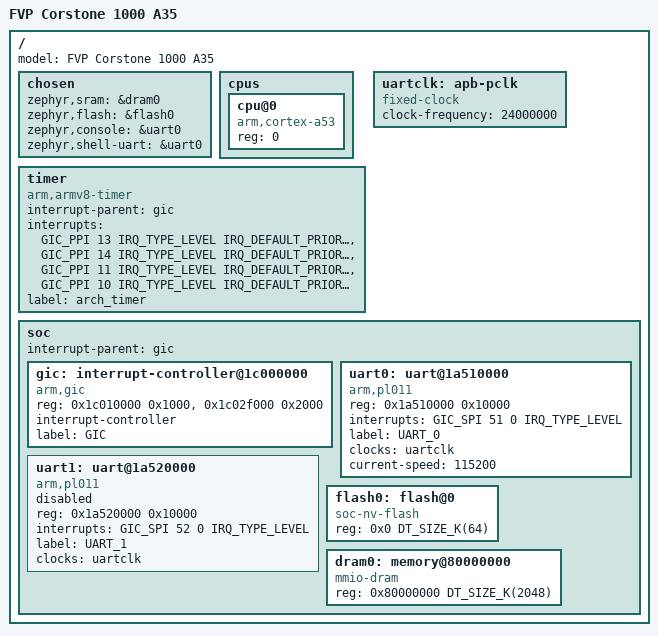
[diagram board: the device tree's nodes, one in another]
/*
 * Copyright (c) 2021 Carlo Caione <ccaione@baylibre.com>
 * SPDX-License-Identifier: Apache-2.0
 */

/dts-v1/;

#include <mem.h>
#include <arm64/armv8-a.dtsi>
#include <dt-bindings/interrupt-controller/arm-gic.h>

/ {
	model = "FVP Corstone 1000 A35";

	chosen {
		/*
		 * The SRAM node is actually located in the
		 * DRAM region of the FVP Base RevC 2xAEMv8A.
		 */
		zephyr,sram = &dram0;
		zephyr,flash = &flash0;
		zephyr,console = &uart0;
		zephyr,shell-uart = &uart0;
	};

	cpus {
		#address-cells = <1>;
		#size-cells = <0>;

		cpu@0 {
			device_type = "cpu";
			compatible = "arm,cortex-a53";
			reg = <0>;
		};
	};

	timer {
		compatible = "arm,armv8-timer";
		interrupt-parent = <&gic>;
		interrupts = <GIC_PPI 13 IRQ_TYPE_LEVEL
			      IRQ_DEFAULT_PRIORITY>,
			     <GIC_PPI 14 IRQ_TYPE_LEVEL
			      IRQ_DEFAULT_PRIORITY>,
			     <GIC_PPI 11 IRQ_TYPE_LEVEL
			      IRQ_DEFAULT_PRIORITY>,
			     <GIC_PPI 10 IRQ_TYPE_LEVEL
			      IRQ_DEFAULT_PRIORITY>;
		label = "arch_timer";
	};

	uartclk: apb-pclk {
		compatible = "fixed-clock";
		clock-frequency = <24000000>;
		#clock-cells = <0>;
	};

	soc {
		interrupt-parent = <&gic>;

		gic: interrupt-controller@1c000000 {
			compatible = "arm,gic";
			reg = <0x1c010000 0x1000>, // GIC Distributor
			      <0x1c02f000 0x2000>; // GIC CPU Interface
			interrupt-controller;
			#interrupt-cells = <4>;
			label = "GIC";
			status = "okay";
			#address-cells = <1>;
			#size-cells = <1>;
		};

		uart0: uart@1a510000 {
			compatible = "arm,pl011";
			reg = <0x1a510000 0x10000>;
			status = "disabled";
			interrupts = <GIC_SPI 51 0 IRQ_TYPE_LEVEL>;
			interrupt-names = "irq_51";
			label = "UART_0";
			clocks = <&uartclk>;
		};

		uart1: uart@1a520000 {
			compatible = "arm,pl011";
			reg = <0x1a520000 0x10000>;
			status = "disabled";
			interrupts = <GIC_SPI 52 0 IRQ_TYPE_LEVEL>;
			interrupt-names = "irq_52";
			label = "UART_1";
			clocks = <&uartclk>;
		};

		flash0: flash@0 {
			compatible = "soc-nv-flash";
			reg = <0x0 DT_SIZE_K(64)>;
		};

		dram0: memory@80000000 {
			compatible = "mmio-dram";
			reg = <0x80000000 DT_SIZE_K(2048)>;
		};
	};
};

&uart0 {
	status = "okay";
	current-speed = <115200>;
};
